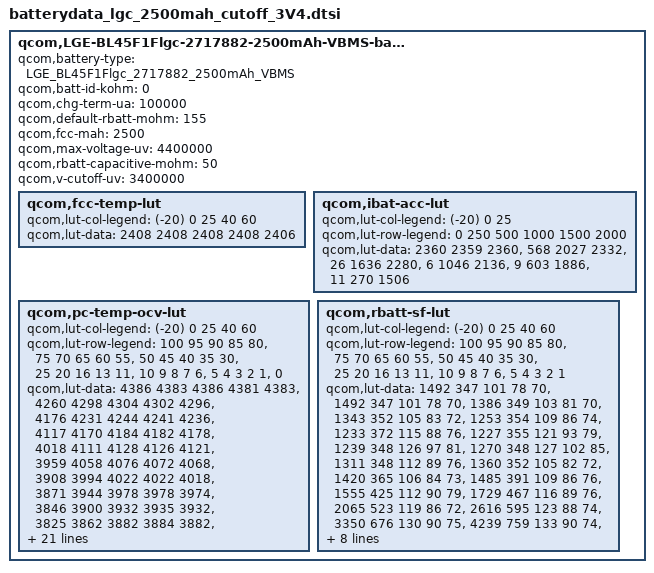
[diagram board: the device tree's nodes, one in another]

qcom,LGE-BL45F1Flgc-2717882-2500mAh-VBMS-batterydata {
	qcom,battery-type = "LGE_BL45F1Flgc_2717882_2500mAh_VBMS";
	qcom,batt-id-kohm = <0>;
	qcom,chg-term-ua = <100000>;
	qcom,default-rbatt-mohm = <155>;
	qcom,fcc-mah = <2500>;
	qcom,max-voltage-uv = <4400000>;
	qcom,rbatt-capacitive-mohm = <50>;
	qcom,v-cutoff-uv = <3400000>;

	qcom,fcc-temp-lut {
		qcom,lut-col-legend = <(-20) 0 25 40 60>;
		qcom,lut-data = <2408 2408 2408 2408 2406>;
	};

	qcom,ibat-acc-lut {
		qcom,lut-col-legend = <(-20) 0 25>;
		qcom,lut-row-legend = <0 250 500 1000 1500 2000>;
		qcom,lut-data = <2360 2359 2360>,
				<568 2027 2332>,
				<26 1636 2280>,
				<6 1046 2136>,
				<9 603 1886>,
				<11 270 1506>;
	};

	qcom,pc-temp-ocv-lut {
		qcom,lut-col-legend = <(-20) 0 25 40 60>;
		qcom,lut-row-legend = <100 95 90 85 80>,
					<75 70 65 60 55>,
					<50 45 40 35 30>,
					<25 20 16 13 11>,
					<10 9 8 7 6>,
					<5 4 3 2 1>,
					<0>;
		qcom,lut-data = <4386 4383 4386 4381 4383>,
				<4260 4298 4304 4302 4296>,
				<4176 4231 4244 4241 4236>,
				<4117 4170 4184 4182 4178>,
				<4018 4111 4128 4126 4121>,
				<3959 4058 4076 4072 4068>,
				<3908 3994 4022 4022 4018>,
				<3871 3944 3978 3978 3974>,
				<3846 3900 3932 3935 3932>,
				<3825 3862 3882 3884 3882>,
				<3806 3828 3846 3846 3844>,
				<3788 3804 3819 3820 3818>,
				<3771 3788 3798 3798 3796>,
				<3753 3774 3782 3782 3780>,
				<3736 3761 3768 3765 3757>,
				<3717 3744 3754 3746 3733>,
				<3697 3724 3732 3723 3710>,
				<3677 3706 3707 3699 3686>,
				<3658 3692 3683 3675 3664>,
				<3640 3680 3676 3669 3658>,
				<3632 3675 3672 3667 3656>,
				<3620 3668 3668 3663 3652>,
				<3607 3661 3664 3660 3648>,
				<3594 3652 3658 3654 3640>,
				<3576 3636 3642 3635 3617>,
				<3551 3610 3609 3599 3578>,
				<3516 3566 3558 3547 3525>,
				<3462 3504 3492 3482 3458>,
				<3382 3418 3404 3392 3368>,
				<3254 3284 3271 3260 3232>,
				<3000 3000 3000 3000 3000>;
	};

	qcom,rbatt-sf-lut {
		qcom,lut-col-legend = <(-20) 0 25 40 60>;
		qcom,lut-row-legend = <100 95 90 85 80>,
					<75 70 65 60 55>,
					<50 45 40 35 30>,
					<25 20 16 13 11>,
					<10 9 8 7 6>,
					<5 4 3 2 1>;
		qcom,lut-data = <1492 347 101 78 70>,
				<1492 347 101 78 70>,
				<1386 349 103 81 70>,
				<1343 352 105 83 72>,
				<1253 354 109 86 74>,
				<1233 372 115 88 76>,
				<1227 355 121 93 79>,
				<1239 348 126 97 81>,
				<1270 348 127 102 85>,
				<1311 348 112 89 76>,
				<1360 352 105 82 72>,
				<1420 365 106 84 73>,
				<1485 391 109 86 76>,
				<1555 425 112 90 79>,
				<1729 467 116 89 76>,
				<2065 523 119 86 72>,
				<2616 595 123 88 74>,
				<3350 676 130 90 75>,
				<4239 759 133 90 74>,
				<5369 844 145 95 76>,
				<5965 889 150 98 77>,
				<6859 946 159 101 80>,
				<7893 1013 170 106 82>,
				<9025 1054 177 108 82>,
				<10827 1130 182 106 80>,
				<13654 1292 189 105 79>,
				<17734 1615 206 110 82>,
				<23832 2245 238 117 86>,
				<33359 3335 294 132 95>,
				<48066 5248 438 175 130>;
	};
};
